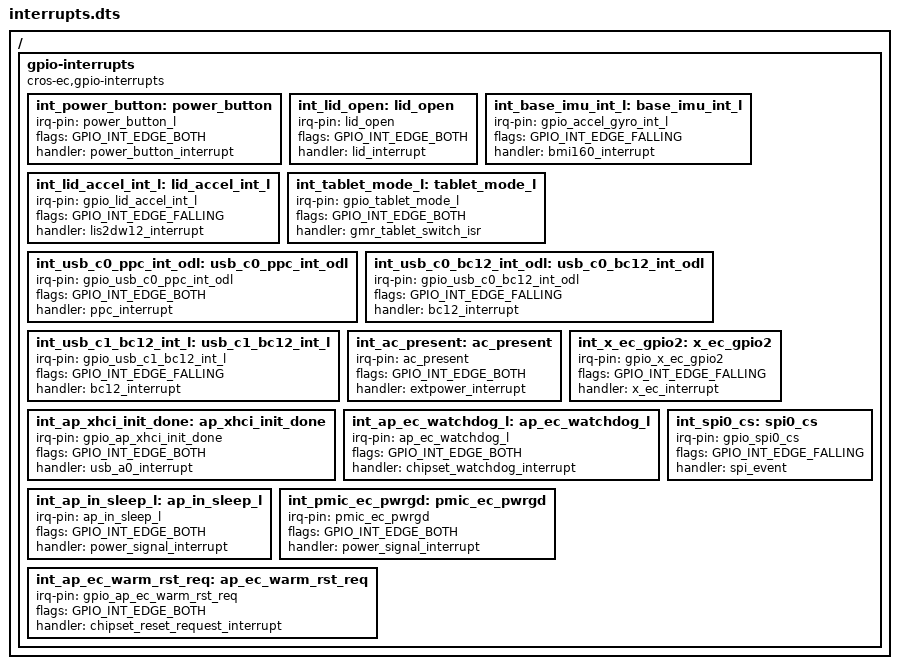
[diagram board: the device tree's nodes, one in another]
/* Copyright 2022 The Chromium OS Authors. All rights reserved.
 * Use of this source code is governed by a BSD-style license that can be
 * found in the LICENSE file.
 */

/ {
	gpio-interrupts {
		compatible = "cros-ec,gpio-interrupts";

		int_power_button: power_button {
			irq-pin = <&power_button_l>;
			flags = <GPIO_INT_EDGE_BOTH>;
			handler = "power_button_interrupt";
		};
		int_lid_open: lid_open {
			irq-pin = <&lid_open>;
			flags = <GPIO_INT_EDGE_BOTH>;
			handler = "lid_interrupt";
		};
		int_base_imu_int_l: base_imu_int_l {
			irq-pin = <&gpio_accel_gyro_int_l>;
			flags = <GPIO_INT_EDGE_FALLING>;
			handler = "bmi160_interrupt";
		};
		int_lid_accel_int_l: lid_accel_int_l {
			irq-pin = <&gpio_lid_accel_int_l>;
			flags = <GPIO_INT_EDGE_FALLING>;
			handler = "lis2dw12_interrupt";
		};
		int_tablet_mode_l: tablet_mode_l {
			irq-pin = <&gpio_tablet_mode_l>;
			flags = <GPIO_INT_EDGE_BOTH>;
			handler = "gmr_tablet_switch_isr";
		};
		int_usb_c0_ppc_int_odl: usb_c0_ppc_int_odl {
			irq-pin = <&gpio_usb_c0_ppc_int_odl>;
			flags = <GPIO_INT_EDGE_BOTH>;
			handler = "ppc_interrupt";
		};
		int_usb_c0_bc12_int_odl: usb_c0_bc12_int_odl {
			irq-pin = <&gpio_usb_c0_bc12_int_odl>;
			flags = <GPIO_INT_EDGE_FALLING>;
			handler = "bc12_interrupt";
		};
		int_usb_c1_bc12_int_l: usb_c1_bc12_int_l {
			irq-pin = <&gpio_usb_c1_bc12_int_l>;
			flags = <GPIO_INT_EDGE_FALLING>;
			handler = "bc12_interrupt";
		};
		int_ac_present: ac_present {
			irq-pin = <&ac_present>;
			flags = <GPIO_INT_EDGE_BOTH>;
			handler = "extpower_interrupt";
		};
		int_x_ec_gpio2: x_ec_gpio2 {
			irq-pin = <&gpio_x_ec_gpio2>;
			flags = <GPIO_INT_EDGE_FALLING>;
			handler = "x_ec_interrupt";
		};
		int_ap_xhci_init_done: ap_xhci_init_done {
			irq-pin = <&gpio_ap_xhci_init_done>;
			flags = <GPIO_INT_EDGE_BOTH>;
			handler = "usb_a0_interrupt";
		};
		int_ap_ec_watchdog_l: ap_ec_watchdog_l {
			irq-pin = <&ap_ec_watchdog_l>;
			flags = <GPIO_INT_EDGE_BOTH>;
			handler = "chipset_watchdog_interrupt";
		};
		int_ap_in_sleep_l: ap_in_sleep_l {
			irq-pin = <&ap_in_sleep_l>;
			flags = <GPIO_INT_EDGE_BOTH>;
			handler = "power_signal_interrupt";
		};
		int_pmic_ec_pwrgd: pmic_ec_pwrgd {
			irq-pin = <&pmic_ec_pwrgd>;
			flags = <GPIO_INT_EDGE_BOTH>;
			handler = "power_signal_interrupt";
		};
		int_ap_ec_warm_rst_req: ap_ec_warm_rst_req {
			irq-pin = <&gpio_ap_ec_warm_rst_req>;
			flags = <GPIO_INT_EDGE_BOTH>;
			handler = "chipset_reset_request_interrupt";
		};
		int_ap_in_sleep_l: ap_in_sleep_l {
			irq-pin = <&ap_in_sleep_l>;
			flags = <GPIO_INT_EDGE_BOTH>;
			handler = "power_signal_interrupt";
		};
		int_spi0_cs: spi0_cs {
			irq-pin = <&gpio_spi0_cs>;
			flags = <GPIO_INT_EDGE_FALLING>;
			handler = "spi_event";
		};
	};
};
